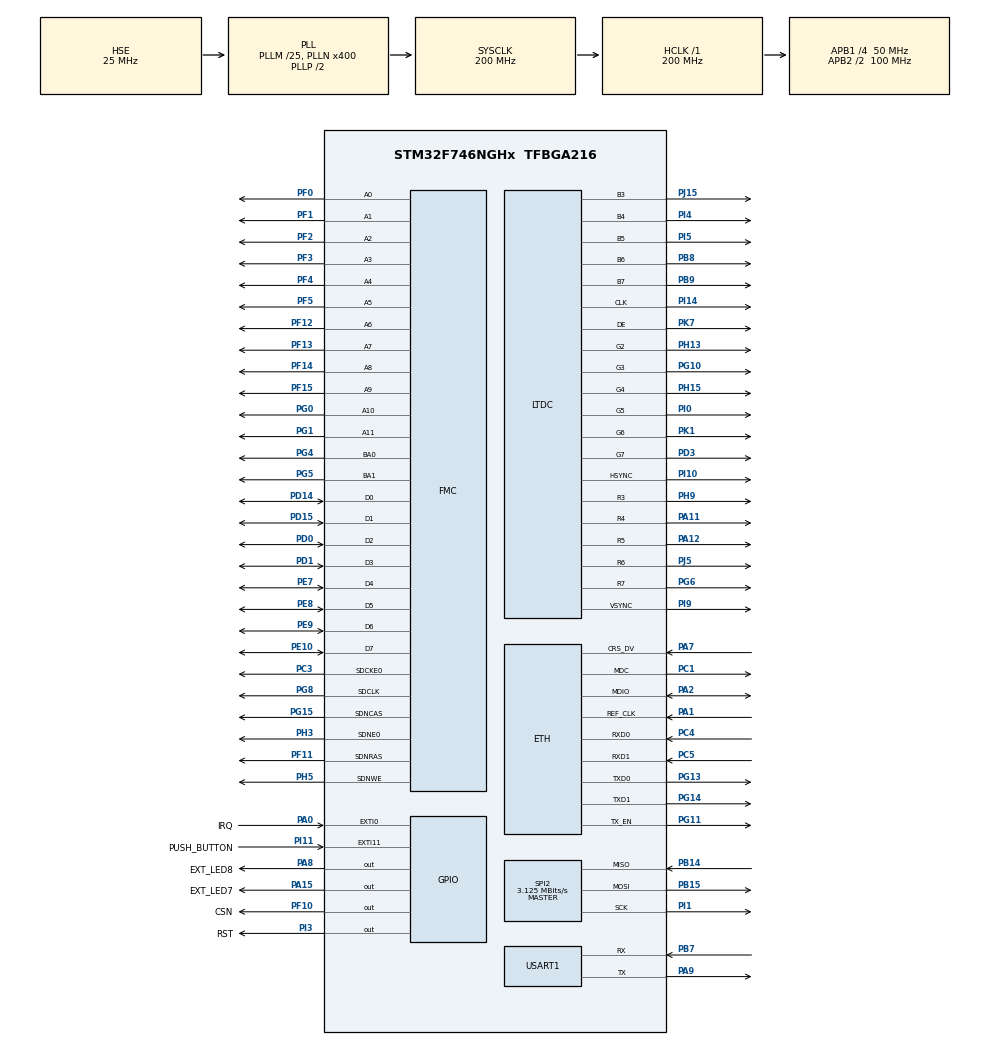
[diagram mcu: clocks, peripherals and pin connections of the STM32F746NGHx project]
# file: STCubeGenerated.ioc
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CORTEX_M7.AccessPermission-Cortex_Memory_Protection_Unit_Region0_Settings=MPU_REGION_FULL_ACCESS
CORTEX_M7.AccessPermission-Cortex_Memory_Protection_Unit_Region1_Settings=MPU_REGION_FULL_ACCESS
CORTEX_M7.AccessPermission-Cortex_Memory_Protection_Unit_Region2_Settings=MPU_REGION_FULL_ACCESS
CORTEX_M7.BaseAddress-Cortex_Memory_Protection_Unit_Region0_Settings=0x20000000
CORTEX_M7.BaseAddress-Cortex_Memory_Protection_Unit_Region1_Settings=0x2004C000
CORTEX_M7.BaseAddress-Cortex_Memory_Protection_Unit_Region2_Settings=0xC0000000
CORTEX_M7.CPU_DCache=Enabled
CORTEX_M7.CPU_ICache=Enabled
CORTEX_M7.DisableExec-Cortex_Memory_Protection_Unit_Region0_Settings=MPU_INSTRUCTION_ACCESS_DISABLE
CORTEX_M7.DisableExec-Cortex_Memory_Protection_Unit_Region1_Settings=MPU_INSTRUCTION_ACCESS_DISABLE
CORTEX_M7.DisableExec-Cortex_Memory_Protection_Unit_Region2_Settings=MPU_INSTRUCTION_ACCESS_DISABLE
CORTEX_M7.Enable-Cortex_Memory_Protection_Unit_Region0_Settings=MPU_REGION_ENABLE
CORTEX_M7.Enable-Cortex_Memory_Protection_Unit_Region1_Settings=MPU_REGION_ENABLE
CORTEX_M7.Enable-Cortex_Memory_Protection_Unit_Region2_Settings=MPU_REGION_ENABLE
CORTEX_M7.IsBufferable-Cortex_Memory_Protection_Unit_Region0_Settings=MPU_ACCESS_BUFFERABLE
CORTEX_M7.IsCacheable-Cortex_Memory_Protection_Unit_Region0_Settings=MPU_ACCESS_CACHEABLE
CORTEX_M7.IsShareable-Cortex_Memory_Protection_Unit_Region0_Settings=MPU_ACCESS_NOT_SHAREABLE
CORTEX_M7.MPU_Control=MPU_PRIVILEGED_DEFAULT
CORTEX_M7.Size-Cortex_Memory_Protection_Unit_Region0_Settings=MPU_REGION_SIZE_512KB
CORTEX_M7.Size-Cortex_Memory_Protection_Unit_Region1_Settings=MPU_REGION_SIZE_16KB
CORTEX_M7.Size-Cortex_Memory_Protection_Unit_Region2_Settings=MPU_REGION_SIZE_16MB
CORTEX_M7.TypeExtField-Cortex_Memory_Protection_Unit_Region0_Settings=MPU_TEX_LEVEL1
CORTEX_M7.TypeExtField-Cortex_Memory_Protection_Unit_Region1_Settings=MPU_TEX_LEVEL1
CORTEX_M7.TypeExtField-Cortex_Memory_Protection_Unit_Region2_Settings=MPU_TEX_LEVEL1
ETH.MediaInterface=HAL_ETH_RMII_MODE
Mcu.Family=STM32F7
Mcu.Name=STM32F746NGHx
Mcu.Package=TFBGA216
NVIC.ETH_IRQn=true\:0\:0\:false\:false\:false\:true\:true\:true
NVIC.EXTI0_IRQn=true\:0\:0\:false\:false\:true\:true\:false\:false
NVIC.EXTI15_10_IRQn=true\:0\:0\:false\:false\:true\:true\:true\:true
NVIC.PriorityGroup=NVIC_PRIORITYGROUP_4
PA0/WKUP.GPIO_Label=IRQ
PA0/WKUP.Signal=GPXTI0
PA1.Mode=RMII
PA1.Signal=ETH_REF_CLK
PA11.Mode=RGB565
PA11.Signal=LTDC_R4
PA12.Mode=RGB565
PA12.Signal=LTDC_R5
PA15.GPIO_Label=EXT_LED7
PA15.Signal=GPIO_Output
PA2.Mode=RMII
PA2.Signal=ETH_MDIO
PA7.Mode=RMII
PA7.Signal=ETH_CRS_DV
PA8.GPIO_Label=EXT_LED8
PA8.Signal=GPIO_Output
PA9.Mode=Asynchronous
PA9.Signal=USART1_TX
PB14.Mode=Full_Duplex_Master
PB14.Signal=SPI2_MISO
PB15.Mode=Full_Duplex_Master
PB15.Signal=SPI2_MOSI
PB7.Mode=Asynchronous
PB7.Signal=USART1_RX
PB8.Mode=RGB565
PB8.Signal=LTDC_B6
PB9.Mode=RGB565
PB9.Signal=LTDC_B7
PC1.Mode=RMII
PC1.Signal=ETH_MDC
PC3.Mode=SdramChipSelect1_1
PC3.Signal=FMC_SDCKE0
PC4.Mode=RMII
PC4.Signal=ETH_RXD0
PC5.Mode=RMII
PC5.Signal=ETH_RXD1
PD0.Signal=FMC_D2_DA2
PD1.Signal=FMC_D3_DA3
PD10.Signal=FMC_D15_DA15
PD11.Signal=FMC_A16_CLE
PD14.Signal=FMC_D0_DA0
PD15.Signal=FMC_D1_DA1
PD3.Mode=RGB565
PD3.Signal=LTDC_G7
PD8.Signal=FMC_D13_DA13
PD9.Signal=FMC_D14_DA14
PE0.Signal=FMC_NBL0
PE1.Signal=FMC_NBL1
PE10.Signal=FMC_D7_DA7
PE11.Signal=FMC_D8_DA8
PE12.Signal=FMC_D9_DA9
PE13.Signal=FMC_D10_DA10
PE14.Signal=FMC_D11_DA11
PE15.Signal=FMC_D12_DA12
PE7.Signal=FMC_D4_DA4
PE8.Signal=FMC_D5_DA5
PE9.Signal=FMC_D6_DA6
PF0.Signal=FMC_A0
PF1.Signal=FMC_A1
PF10.GPIO_Label=CSN
PF10.Signal=GPIO_Output
PF11.Signal=FMC_SDNRAS
PF12.Signal=FMC_A6
PF13.Signal=FMC_A7
PF14.Signal=FMC_A8
PF15.Signal=FMC_A9
PF2.Signal=FMC_A2
PF3.Signal=FMC_A3
PF4.Signal=FMC_A4
PF5.Signal=FMC_A5
PG0.Signal=FMC_A10
PG1.Signal=FMC_A11
PG10.Mode=RGB565
PG10.Signal=LTDC_G3
PG11.Mode=RMII
PG11.Signal=ETH_TX_EN
PG13.Mode=RMII
PG13.Signal=ETH_TXD0
PG14.Mode=RMII
PG14.Signal=ETH_TXD1
PG15.Signal=FMC_SDNCAS
PG4.Signal=FMC_A14_BA0
PG5.Signal=FMC_A15_BA1
PG6.Mode=RGB565
PG6.Signal=LTDC_R7
PG8.Signal=FMC_SDCLK
PH0/OSC_IN.Mode=HSE-External-Oscillator
PH0/OSC_IN.Signal=RCC_OSC_IN
PH1/OSC_OUT.Mode=HSE-External-Oscillator
PH1/OSC_OUT.Signal=RCC_OSC_OUT
PH13.Mode=RGB565
PH13.Signal=LTDC_G2
PH15.Mode=RGB565
PH15.Signal=LTDC_G4
PH3.Mode=SdramChipSelect1_1
PH3.Signal=FMC_SDNE0
PH5.Signal=FMC_SDNWE
PH9.Mode=RGB565
PH9.Signal=LTDC_R3
PI0.Mode=RGB565
PI0.Signal=LTDC_G5
PI1.Mode=Full_Duplex_Master
PI1.Signal=SPI2_SCK
PI10.Mode=RGB565
PI10.Signal=LTDC_HSYNC
PI11.GPIO_Label=PUSH_BUTTON
PI11.Signal=GPXTI11
PI14.Mode=RGB565
PI14.Signal=LTDC_CLK
PI3.GPIO_Label=RST
PI3.Signal=GPIO_Output
PI4.Mode=RGB565
PI4.Signal=LTDC_B4
PI5.Mode=RGB565
PI5.Signal=LTDC_B5
PI9.Mode=RGB565
PI9.Signal=LTDC_VSYNC
PJ15.Mode=RGB565
PJ15.Signal=LTDC_B3
PJ5.Mode=RGB565
PJ5.Signal=LTDC_R6
PK1.Mode=RGB565
PK1.Signal=LTDC_G6
PK7.Mode=RGB565
PK7.Signal=LTDC_DE
ProjectManager.HeapSize=0x200
ProjectManager.StackSize=0x400
ProjectManager.TargetToolchain=MDK-ARM V5
RCC.AHBFreq_Value=200000000
RCC.APB1CLKDivider=RCC_HCLK_DIV4
RCC.APB1Freq_Value=50000000
RCC.APB1TimFreq_Value=100000000
RCC.APB2CLKDivider=RCC_HCLK_DIV2
RCC.APB2Freq_Value=100000000
RCC.APB2TimFreq_Value=200000000
RCC.CortexFreq_Value=200000000
RCC.HCLKFreq_Value=200000000
RCC.HSE_VALUE=25000000
RCC.HSI_VALUE=16000000
RCC.LSE_VALUE=32768
RCC.PLLM=25
RCC.PLLN=400
RCC.PLLSAIRDiv=RCC_PLLSAIDIVR_4
RCC.PLLSourceVirtual=RCC_PLLSOURCE_HSE
RCC.SYSCLKFreq_VALUE=200000000
RCC.SYSCLKSource=RCC_SYSCLKSOURCE_PLLCLK
RCC.USBFreq_Value=200000000
RCC.VCOOutputFreq_Value=400000000
SH.FMC_A0.0=FMC_A0,12b-sda1
SH.FMC_A1.0=FMC_A1,12b-sda1
SH.FMC_A10.0=FMC_A10,12b-sda1
SH.FMC_A11.0=FMC_A11,12b-sda1
SH.FMC_A14_BA0.0=FMC_BA0,FourSdramBanks1
SH.FMC_A15_BA1.0=FMC_BA1,FourSdramBanks1
SH.FMC_A16_CLE.0=FMC_A16
SH.FMC_A2.0=FMC_A2,12b-sda1
SH.FMC_A3.0=FMC_A3,12b-sda1
SH.FMC_A4.0=FMC_A4,12b-sda1
SH.FMC_A5.0=FMC_A5,12b-sda1
SH.FMC_A6.0=FMC_A6,12b-sda1
SH.FMC_A7.0=FMC_A7,12b-sda1
SH.FMC_A8.0=FMC_A8,12b-sda1
SH.FMC_A9.0=FMC_A9,12b-sda1
SH.FMC_D0_DA0.0=FMC_D0,sd-8b-d1
SH.FMC_D10_DA10.0=FMC_D10
SH.FMC_D11_DA11.0=FMC_D11
SH.FMC_D12_DA12.0=FMC_D12
SH.FMC_D13_DA13.0=FMC_D13
SH.FMC_D14_DA14.0=FMC_D14
SH.FMC_D15_DA15.0=FMC_D15
SH.FMC_D1_DA1.0=FMC_D1,sd-8b-d1
SH.FMC_D2_DA2.0=FMC_D2,sd-8b-d1
SH.FMC_D3_DA3.0=FMC_D3,sd-8b-d1
SH.FMC_D4_DA4.0=FMC_D4,sd-8b-d1
SH.FMC_D5_DA5.0=FMC_D5,sd-8b-d1
SH.FMC_D6_DA6.0=FMC_D6,sd-8b-d1
SH.FMC_D7_DA7.0=FMC_D7,sd-8b-d1
SH.FMC_D8_DA8.0=FMC_D8
SH.FMC_D9_DA9.0=FMC_D9
SH.FMC_NBL0.0=FMC_NBL0
SH.FMC_NBL1.0=FMC_NBL1
SH.FMC_SDCLK.0=FMC_SDCLK,12b-sda1
SH.FMC_SDNCAS.0=FMC_SDNCAS,12b-sda1
SH.FMC_SDNRAS.0=FMC_SDNRAS,12b-sda1
SH.FMC_SDNWE.0=FMC_SDNWE,12b-sda1
SPI2.BaudRatePrescaler=SPI_BAUDRATEPRESCALER_16
SPI2.CalculateBaudRate=3.125 MBits/s
SPI2.DataSize=SPI_DATASIZE_8BIT
SPI2.Direction=SPI_DIRECTION_2LINES
SPI2.Mode=SPI_MODE_MASTER
SPI2.VirtualType=VM_MASTER
STMicroelectronics.X-CUBE-BLE1.7.0.0.BLE1IiApplicationsCcDeviceJjApplication=SensorDemoBLESensor
STMicroelectronics.X-CUBE-BLE1.7.0.0.BLE1_DEBUG=1
STMicroelectronics.X-CUBE-BLE1.7.0.0.BlueNRGAaMSCcWirelessJjBlueNRGAaMSJjController=true
STMicroelectronics.X-CUBE-BLE1.7.0.0.BlueNRGAaMSCcWirelessJjBlueNRGAaMSJjHCIIiTL=Basic
STMicroelectronics.X-CUBE-BLE1.7.0.0.BlueNRGAaMSCcWirelessJjBlueNRGAaMSJjHCIIiTLIiINTERFACE=Template
STMicroelectronics.X-CUBE-BLE1.7.0.0.BlueNRGAaMSCcWirelessJjBlueNRGAaMSJjUtils=true
USART1.VirtualMode-Asynchronous=VM_ASYNC
VP_DMA2D_VS_DMA2D.Mode=DMA2D_Activate
VP_STMicroelectronics.X-CUBE-BLE1_VS_DeviceJjBLE1IiApplications_7.0.0.Mode=DeviceJjBLE1IiApplications
VP_STMicroelectronics.X-CUBE-BLE1_VS_WirelessJjBlueNRGAaMS_7.0.0.Mode=WirelessJjBlueNRGAaMS
board=STCubeGenerated

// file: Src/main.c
/* USER CODE BEGIN Header */
/**
  ******************************************************************************
  * @file           : main.c
  * @brief          : Main program body
  ******************************************************************************
  * @attention
  *
  * <h2><center>&copy; Copyright (c) 2019 STMicroelectronics.
  * All rights reserved.</center></h2>
  *
  * This software component is licensed by ST under BSD 3-Clause license,
  * the "License"; You may not use this file except in compliance with the
  * License. You may obtain a copy of the License at:
  *                        opensource.org/licenses/BSD-3-Clause
  *
  ******************************************************************************
  */
/* USER CODE END Header */
#include "main.h"
#include "string.h"
#include "app_bluenrg_ms.h"

/* USER CODE BEGIN Includes */
#include <stdio.h>
/* USER CODE END Includes */

#if defined ( __ICCARM__ ) /*!< IAR Compiler */
#pragma location=0x2004c000
ETH_DMADescTypeDef  DMARxDscrTab[ETH_RX_DESC_CNT]; /* Ethernet Rx DMA Descriptors */
#pragma location=0x2004c0a0
ETH_DMADescTypeDef  DMATxDscrTab[ETH_TX_DESC_CNT]; /* Ethernet Tx DMA Descriptors */

#elif defined ( __CC_ARM )  /* MDK ARM Compiler */

__attribute__((at(0x2004c000))) ETH_DMADescTypeDef  DMARxDscrTab[ETH_RX_DESC_CNT]; /* Ethernet Rx DMA Descriptors */
__attribute__((at(0x2004c0a0))) ETH_DMADescTypeDef  DMATxDscrTab[ETH_TX_DESC_CNT]; /* Ethernet Tx DMA Descriptors */

#elif defined ( __GNUC__ ) /* GNU Compiler */

ETH_DMADescTypeDef DMARxDscrTab[ETH_RX_DESC_CNT] __attribute__((section(".RxDecripSection"))); /* Ethernet Rx DMA Descriptors */
ETH_DMADescTypeDef DMATxDscrTab[ETH_TX_DESC_CNT] __attribute__((section(".TxDecripSection")));   /* Ethernet Tx DMA Descriptors */
#endif

ETH_TxPacketConfig TxConfig;

DMA2D_HandleTypeDef hdma2d;

ETH_HandleTypeDef heth;

LTDC_HandleTypeDef hltdc;

SPI_HandleTypeDef hspi2;

UART_HandleTypeDef huart1;

SDRAM_HandleTypeDef hsdram1;

/* USER CODE BEGIN PV */
/* Private variables ---------------------------------------------------------*/

/* USER CODE END PV */

void SystemClock_Config(void);
static void MPU_Config(void);
static void MX_GPIO_Init(void);
static void MX_FMC_Init(void);
static void MX_USART1_UART_Init(void);
static void MX_DMA2D_Init(void);
static void MX_SPI2_Init(void);
void BSP_PB_Callback(/*Button_TypeDef Button*/);
/* USER CODE BEGIN PFP */
/* Private function prototypes -----------------------------------------------*/
extern void BSP_SDRAM_Init(void);
/* USER CODE END PFP */

/* USER CODE BEGIN 0 */
/**
  * Override default HAL_GetTick function
  */
uint32_t HAL_GetTick (void) {
  static uint32_t ticks = 0U;
         uint32_t i;

  if (osKernelGetState () == osKernelRunning) {
    return ((uint32_t)osKernelGetTickCount ());
  }

  /* If Kernel is not running wait approximately 1 ms then increment
     and return auxiliary tick counter value */
  for (i = (SystemCoreClock >> 14U); i > 0U; i--) {
    __NOP(); __NOP(); __NOP(); __NOP(); __NOP(); __NOP();
    __NOP(); __NOP(); __NOP(); __NOP(); __NOP(); __NOP();
  }
  return ++ticks;
}

/**
  * Override default HAL_InitTick function
  */
HAL_StatusTypeDef HAL_InitTick(uint32_t TickPriority) {

  UNUSED(TickPriority);

  return HAL_OK;
}
/* USER CODE END 0 */

int main(void)
{

  /* MPU Configuration--------------------------------------------------------*/
  MPU_Config();

  /* Enable the CPU Cache */

  /* Enable I-Cache---------------------------------------------------------*/
  SCB_EnableICache();

  /* Enable D-Cache---------------------------------------------------------*/
  SCB_EnableDCache();

  /* MCU Configuration--------------------------------------------------------*/

  /* Reset of all peripherals, Initializes the Flash interface and the Systick. */
  HAL_Init();

  /* USER CODE BEGIN Init */
  BSP_SDRAM_Init();                           /* Initialize BSP SDRAM           */
  /* USER CODE END Init */

  /* Configure the system clock */
  SystemClock_Config();

  /* USER CODE BEGIN SysInit */
  SystemCoreClockUpdate();
  /* USER CODE END SysInit */

  /* Initialize all configured peripherals */
  MX_GPIO_Init();
  MX_USART1_UART_Init();
  MX_DMA2D_Init();
  MX_SPI2_Init();
  /* USER CODE BEGIN 2 */
	HAL_GPIO_TogglePin(EXT_LED7_GPIO_Port,EXT_LED7_Pin);
	printf("Hello Vives!\n");

  /* Initialize CMSIS-RTOS2 */
  osKernelInitialize ();

  /* Create application main thread */
  osThreadNew(app_main, NULL, &app_main_attr);
  /* Start thread execution */
  osKernelStart();

  /* USER CODE END 2 */

  /* Infinite loop */
  while (1)
  {

  //MX_BlueNRG_MS_Process();
  }
}

void SystemClock_Config(void)
{
  RCC_OscInitTypeDef RCC_OscInitStruct = {0};
  RCC_ClkInitTypeDef RCC_ClkInitStruct = {0};

  /** Configure the main internal regulator output voltage
  */
  __HAL_RCC_PWR_CLK_ENABLE();
  __HAL_PWR_VOLTAGESCALING_CONFIG(PWR_REGULATOR_VOLTAGE_SCALE1);

  /** Initializes the RCC Oscillators according to the specified parameters
  * in the RCC_OscInitTypeDef structure.
  */
  RCC_OscInitStruct.OscillatorType = RCC_OSCILLATORTYPE_HSE;
  RCC_OscInitStruct.HSEState = RCC_HSE_ON;
  RCC_OscInitStruct.PLL.PLLState = RCC_PLL_ON;
  RCC_OscInitStruct.PLL.PLLSource = RCC_PLLSOURCE_HSE;
  RCC_OscInitStruct.PLL.PLLM = 25;
  RCC_OscInitStruct.PLL.PLLN = 400;
  RCC_OscInitStruct.PLL.PLLP = RCC_PLLP_DIV2;
  RCC_OscInitStruct.PLL.PLLQ = 2;
  if (HAL_RCC_OscConfig(&RCC_OscInitStruct) != HAL_OK)
  {
    Error_Handler();
  }

  /** Activate the Over-Drive mode
  */
  if (HAL_PWREx_EnableOverDrive() != HAL_OK)
  {
    Error_Handler();
  }

  /** Initializes the CPU, AHB and APB buses clocks
  */
  RCC_ClkInitStruct.ClockType = RCC_CLOCKTYPE_HCLK|RCC_CLOCKTYPE_SYSCLK
                              |RCC_CLOCKTYPE_PCLK1|RCC_CLOCKTYPE_PCLK2;
  RCC_ClkInitStruct.SYSCLKSource = RCC_SYSCLKSOURCE_PLLCLK;
  RCC_ClkInitStruct.AHBCLKDivider = RCC_SYSCLK_DIV1;
  RCC_ClkInitStruct.APB1CLKDivider = RCC_HCLK_DIV4;
  RCC_ClkInitStruct.APB2CLKDivider = RCC_HCLK_DIV2;

  if (HAL_RCC_ClockConfig(&RCC_ClkInitStruct, FLASH_LATENCY_6) != HAL_OK)
  {
    Error_Handler();
  }
}

static void MX_DMA2D_Init(void)
{

  hdma2d.Instance = DMA2D;
  hdma2d.Init.Mode = DMA2D_M2M;
  hdma2d.Init.ColorMode = DMA2D_OUTPUT_ARGB8888;
  hdma2d.Init.OutputOffset = 0;
  hdma2d.LayerCfg[1].InputOffset = 0;
  hdma2d.LayerCfg[1].InputColorMode = DMA2D_INPUT_ARGB8888;
  hdma2d.LayerCfg[1].AlphaMode = DMA2D_NO_MODIF_ALPHA;
  hdma2d.LayerCfg[1].InputAlpha = 0;
  if (HAL_DMA2D_Init(&hdma2d) != HAL_OK)
  {
    Error_Handler();
  }
  if (HAL_DMA2D_ConfigLayer(&hdma2d, 1) != HAL_OK)
  {
    Error_Handler();
  }

}

void MX_ETH_Init(void)
{

   static uint8_t MACAddr[6];

  heth.Instance = ETH;
  MACAddr[0] = 0x00;
  MACAddr[1] = 0x80;
  MACAddr[2] = 0xE1;
  MACAddr[3] = 0x00;
  MACAddr[4] = 0x00;
  MACAddr[5] = 0x00;
  heth.Init.MACAddr = &MACAddr[0];
  heth.Init.MediaInterface = HAL_ETH_RMII_MODE;
  heth.Init.TxDesc = DMATxDscrTab;
  heth.Init.RxDesc = DMARxDscrTab;
  heth.Init.RxBuffLen = 1524;

  if (HAL_ETH_Init(&heth) != HAL_OK)
  {
    Error_Handler();
  }

  memset(&TxConfig, 0 , sizeof(ETH_TxPacketConfig));
  TxConfig.Attributes = ETH_TX_PACKETS_FEATURES_CSUM | ETH_TX_PACKETS_FEATURES_CRCPAD;
  TxConfig.ChecksumCtrl = ETH_CHECKSUM_IPHDR_PAYLOAD_INSERT_PHDR_CALC;
  TxConfig.CRCPadCtrl = ETH_CRC_PAD_INSERT;

}

void MX_LTDC_Init(void)
{

  LTDC_LayerCfgTypeDef pLayerCfg = {0};
  LTDC_LayerCfgTypeDef pLayerCfg1 = {0};

  hltdc.Instance = LTDC;
  hltdc.Init.HSPolarity = LTDC_HSPOLARITY_AL;
  hltdc.Init.VSPolarity = LTDC_VSPOLARITY_AL;
  hltdc.Init.DEPolarity = LTDC_DEPOLARITY_AL;
  hltdc.Init.PCPolarity = LTDC_PCPOLARITY_IPC;
  hltdc.Init.HorizontalSync = 7;
  hltdc.Init.VerticalSync = 3;
  hltdc.Init.AccumulatedHBP = 14;
  hltdc.Init.AccumulatedVBP = 5;
  hltdc.Init.AccumulatedActiveW = 654;
  hltdc.Init.AccumulatedActiveH = 485;
  hltdc.Init.TotalWidth = 660;
  hltdc.Init.TotalHeigh = 487;
  hltdc.Init.Backcolor.Blue = 0;
  hltdc.Init.Backcolor.Green = 0;
  hltdc.Init.Backcolor.Red = 0;
  if (HAL_LTDC_Init(&hltdc) != HAL_OK)
  {
    Error_Handler();
  }
  pLayerCfg.WindowX0 = 0;
  pLayerCfg.WindowX1 = 0;
  pLayerCfg.WindowY0 = 0;
  pLayerCfg.WindowY1 = 0;
  pLayerCfg.PixelFormat = LTDC_PIXEL_FORMAT_ARGB8888;
  pLayerCfg.Alpha = 0;
  pLayerCfg.Alpha0 = 0;
  pLayerCfg.BlendingFactor1 = LTDC_BLENDING_FACTOR1_CA;
  pLayerCfg.BlendingFactor2 = LTDC_BLENDING_FACTOR2_CA;
  pLayerCfg.FBStartAdress = 0;
  pLayerCfg.ImageWidth = 0;
  pLayerCfg.ImageHeight = 0;
  pLayerCfg.Backcolor.Blue = 0;
  pLayerCfg.Backcolor.Green = 0;
  pLayerCfg.Backcolor.Red = 0;
  if (HAL_LTDC_ConfigLayer(&hltdc, &pLayerCfg, 0) != HAL_OK)
  {
    Error_Handler();
  }
  pLayerCfg1.WindowX0 = 0;
  pLayerCfg1.WindowX1 = 0;
  pLayerCfg1.WindowY0 = 0;
  pLayerCfg1.WindowY1 = 0;
  pLayerCfg1.PixelFormat = LTDC_PIXEL_FORMAT_ARGB8888;
  pLayerCfg1.Alpha = 0;
  pLayerCfg1.Alpha0 = 0;
  pLayerCfg1.BlendingFactor1 = LTDC_BLENDING_FACTOR1_CA;
  pLayerCfg1.BlendingFactor2 = LTDC_BLENDING_FACTOR2_CA;
  pLayerCfg1.FBStartAdress = 0;
  pLayerCfg1.ImageWidth = 0;
  pLayerCfg1.ImageHeight = 0;
  pLayerCfg1.Backcolor.Blue = 0;
  pLayerCfg1.Backcolor.Green = 0;
  pLayerCfg1.Backcolor.Red = 0;
  if (HAL_LTDC_ConfigLayer(&hltdc, &pLayerCfg1, 1) != HAL_OK)
  {
    Error_Handler();
  }

}

static void MX_SPI2_Init(void)
{

  /* SPI2 parameter configuration*/
  hspi2.Instance = SPI2;
  hspi2.Init.Mode = SPI_MODE_MASTER;
  hspi2.Init.Direction = SPI_DIRECTION_2LINES;
  hspi2.Init.DataSize = SPI_DATASIZE_8BIT;
  hspi2.Init.CLKPolarity = SPI_POLARITY_LOW;
  hspi2.Init.CLKPhase = SPI_PHASE_1EDGE;
  hspi2.Init.NSS = SPI_NSS_SOFT;
  hspi2.Init.BaudRatePrescaler = SPI_BAUDRATEPRESCALER_16;
  hspi2.Init.FirstBit = SPI_FIRSTBIT_MSB;
  hspi2.Init.TIMode = SPI_TIMODE_DISABLE;
  hspi2.Init.CRCCalculation = SPI_CRCCALCULATION_DISABLE;
  hspi2.Init.CRCPolynomial = 7;
  hspi2.Init.CRCLength = SPI_CRC_LENGTH_DATASIZE;
  hspi2.Init.NSSPMode = SPI_NSS_PULSE_ENABLE;
  if (HAL_SPI_Init(&hspi2) != HAL_OK)
  {
    Error_Handler();
  }

}

static void MX_USART1_UART_Init(void)
{

  huart1.Instance = USART1;
  huart1.Init.BaudRate = 115200;
  huart1.Init.WordLength = UART_WORDLENGTH_8B;
  huart1.Init.StopBits = UART_STOPBITS_1;
  huart1.Init.Parity = UART_PARITY_NONE;
  huart1.Init.Mode = UART_MODE_TX_RX;
  huart1.Init.HwFlowCtl = UART_HWCONTROL_NONE;
  huart1.Init.OverSampling = UART_OVERSAMPLING_16;
  huart1.Init.OneBitSampling = UART_ONE_BIT_SAMPLE_DISABLE;
  huart1.AdvancedInit.AdvFeatureInit = UART_ADVFEATURE_NO_INIT;
  if (HAL_UART_Init(&huart1) != HAL_OK)
  {
    Error_Handler();
  }

}

/* FMC initialization function */
static void MX_FMC_Init(void)
{

  FMC_SDRAM_TimingTypeDef SdramTiming = {0};

  /** Perform the SDRAM1 memory initialization sequence
  */
  hsdram1.Instance = FMC_SDRAM_DEVICE;
  /* hsdram1.Init */
  hsdram1.Init.SDBank = FMC_SDRAM_BANK1;
  hsdram1.Init.ColumnBitsNumber = FMC_SDRAM_COLUMN_BITS_NUM_8;
  hsdram1.Init.RowBitsNumber = FMC_SDRAM_ROW_BITS_NUM_12;
  hsdram1.Init.MemoryDataWidth = FMC_SDRAM_MEM_BUS_WIDTH_8;
  hsdram1.Init.InternalBankNumber = FMC_SDRAM_INTERN_BANKS_NUM_4;
  hsdram1.Init.CASLatency = FMC_SDRAM_CAS_LATENCY_1;
  hsdram1.Init.WriteProtection = FMC_SDRAM_WRITE_PROTECTION_DISABLE;
  hsdram1.Init.SDClockPeriod = FMC_SDRAM_CLOCK_DISABLE;
  hsdram1.Init.ReadBurst = FMC_SDRAM_RBURST_DISABLE;
  hsdram1.Init.ReadPipeDelay = FMC_SDRAM_RPIPE_DELAY_0;
  /* SdramTiming */
  SdramTiming.LoadToActiveDelay = 16;
  SdramTiming.ExitSelfRefreshDelay = 16;
  SdramTiming.SelfRefreshTime = 16;
  SdramTiming.RowCycleDelay = 16;
  SdramTiming.WriteRecoveryTime = 16;
  SdramTiming.RPDelay = 16;
  SdramTiming.RCDDelay = 16;

  if (HAL_SDRAM_Init(&hsdram1, &SdramTiming) != HAL_OK)
  {
    Error_Handler( );
  }

}

static void MX_GPIO_Init(void)
{
  GPIO_InitTypeDef GPIO_InitStruct = {0};

  /* GPIO Ports Clock Enable */
  __HAL_RCC_GPIOG_CLK_ENABLE();
  __HAL_RCC_GPIOE_CLK_ENABLE();
  __HAL_RCC_GPIOB_CLK_ENABLE();
  __HAL_RCC_GPIOA_CLK_ENABLE();
  __HAL_RCC_GPIOD_CLK_ENABLE();
  __HAL_RCC_GPIOI_CLK_ENABLE();
  __HAL_RCC_GPIOK_CLK_ENABLE();
  __HAL_RCC_GPIOF_CLK_ENABLE();
  __HAL_RCC_GPIOJ_CLK_ENABLE();
  __HAL_RCC_GPIOH_CLK_ENABLE();
  __HAL_RCC_GPIOC_CLK_ENABLE();

  /*Configure GPIO pin Output Level */
  HAL_GPIO_WritePin(GPIOA, EXT_LED8_Pin|EXT_LED7_Pin, GPIO_PIN_RESET);

  /*Configure GPIO pin Output Level */
  HAL_GPIO_WritePin(RST_GPIO_Port, RST_Pin, GPIO_PIN_RESET);

  /*Configure GPIO pin Output Level */
  HAL_GPIO_WritePin(CSN_GPIO_Port, CSN_Pin, GPIO_PIN_RESET);

  /*Configure GPIO pins : EXT_LED8_Pin EXT_LED7_Pin */
  GPIO_InitStruct.Pin = EXT_LED8_Pin|EXT_LED7_Pin;
  GPIO_InitStruct.Mode = GPIO_MODE_OUTPUT_PP;
  GPIO_InitStruct.Pull = GPIO_NOPULL;
  GPIO_InitStruct.Speed = GPIO_SPEED_FREQ_LOW;
  HAL_GPIO_Init(GPIOA, &GPIO_InitStruct);

  /*Configure GPIO pin : RST_Pin */
  GPIO_InitStruct.Pin = RST_Pin;
  GPIO_InitStruct.Mode = GPIO_MODE_OUTPUT_PP;
  GPIO_InitStruct.Pull = GPIO_NOPULL;
  GPIO_InitStruct.Speed = GPIO_SPEED_FREQ_LOW;
  HAL_GPIO_Init(RST_GPIO_Port, &GPIO_InitStruct);

  /*Configure GPIO pin : PUSH_BUTTON_Pin */
  GPIO_InitStruct.Pin = PUSH_BUTTON_Pin;
  GPIO_InitStruct.Mode = GPIO_MODE_IT_RISING;
  GPIO_InitStruct.Pull = GPIO_NOPULL;
  HAL_GPIO_Init(PUSH_BUTTON_GPIO_Port, &GPIO_InitStruct);

  /*Configure GPIO pin : CSN_Pin */
  GPIO_InitStruct.Pin = CSN_Pin;
  GPIO_InitStruct.Mode = GPIO_MODE_OUTPUT_PP;
  GPIO_InitStruct.Pull = GPIO_NOPULL;
  GPIO_InitStruct.Speed = GPIO_SPEED_FREQ_LOW;
  HAL_GPIO_Init(CSN_GPIO_Port, &GPIO_InitStruct);

  /*Configure GPIO pin : IRQ_Pin */
  GPIO_InitStruct.Pin = IRQ_Pin;
  GPIO_InitStruct.Mode = GPIO_MODE_IT_RISING;
  GPIO_InitStruct.Pull = GPIO_NOPULL;
  HAL_GPIO_Init(IRQ_GPIO_Port, &GPIO_InitStruct);

  /* EXTI interrupt init*/
  HAL_NVIC_SetPriority(EXTI0_IRQn, 0, 0);
  HAL_NVIC_SetPriority(EXTI15_10_IRQn, 0, 0);
  HAL_NVIC_EnableIRQ(EXTI15_10_IRQn);

/* USER CODE BEGIN MX_GPIO_Init_2 */
  /* EXTI interrupt init*/
  HAL_NVIC_SetPriority(EXTI0_IRQn, 0, 0);
  HAL_NVIC_SetPriority(EXTI15_10_IRQn, 0, 0);

/* USER CODE END MX_GPIO_Init_2 */
}

/* USER CODE BEGIN 4 */

void HAL_GPIO_EXTI_Callback(uint16_t GPIO_Pin)
{
	if(GPIO_Pin == PUSH_BUTTON_Pin)
		BSP_PB_Callback();
}

/* USER CODE END 4 */

 /* MPU Configuration */

void MPU_Config(void)
{
  MPU_Region_InitTypeDef MPU_InitStruct = {0};

  /* Disables the MPU */
  HAL_MPU_Disable();

  /** Initializes and configures the Region and the memory to be protected
  */
  MPU_InitStruct.Enable = MPU_REGION_ENABLE;
  MPU_InitStruct.Number = MPU_REGION_NUMBER0;
  MPU_InitStruct.BaseAddress = 0x20000000;
  MPU_InitStruct.Size = MPU_REGION_SIZE_512KB;
  MPU_InitStruct.SubRegionDisable = 0x0;
  MPU_InitStruct.TypeExtField = MPU_TEX_LEVEL1;
  MPU_InitStruct.AccessPermission = MPU_REGION_FULL_ACCESS;
  MPU_InitStruct.DisableExec = MPU_INSTRUCTION_ACCESS_DISABLE;
  MPU_InitStruct.IsShareable = MPU_ACCESS_NOT_SHAREABLE;
  MPU_InitStruct.IsCacheable = MPU_ACCESS_CACHEABLE;
  MPU_InitStruct.IsBufferable = MPU_ACCESS_BUFFERABLE;

  HAL_MPU_ConfigRegion(&MPU_InitStruct);

  /** Initializes and configures the Region and the memory to be protected
  */
  MPU_InitStruct.Number = MPU_REGION_NUMBER1;
  MPU_InitStruct.BaseAddress = 0x2004C000;
  MPU_InitStruct.Size = MPU_REGION_SIZE_16KB;
  MPU_InitStruct.IsCacheable = MPU_ACCESS_NOT_CACHEABLE;
  MPU_InitStruct.IsBufferable = MPU_ACCESS_NOT_BUFFERABLE;

  HAL_MPU_ConfigRegion(&MPU_InitStruct);

  /** Initializes and configures the Region and the memory to be protected
  */
  MPU_InitStruct.Number = MPU_REGION_NUMBER2;
  MPU_InitStruct.BaseAddress = 0xC0000000;
  MPU_InitStruct.Size = MPU_REGION_SIZE_16MB;

  HAL_MPU_ConfigRegion(&MPU_InitStruct);
  /* Enables the MPU */
  HAL_MPU_Enable(MPU_PRIVILEGED_DEFAULT);

}

void Error_Handler(void)
{
  while(1)
  {
  }
}
